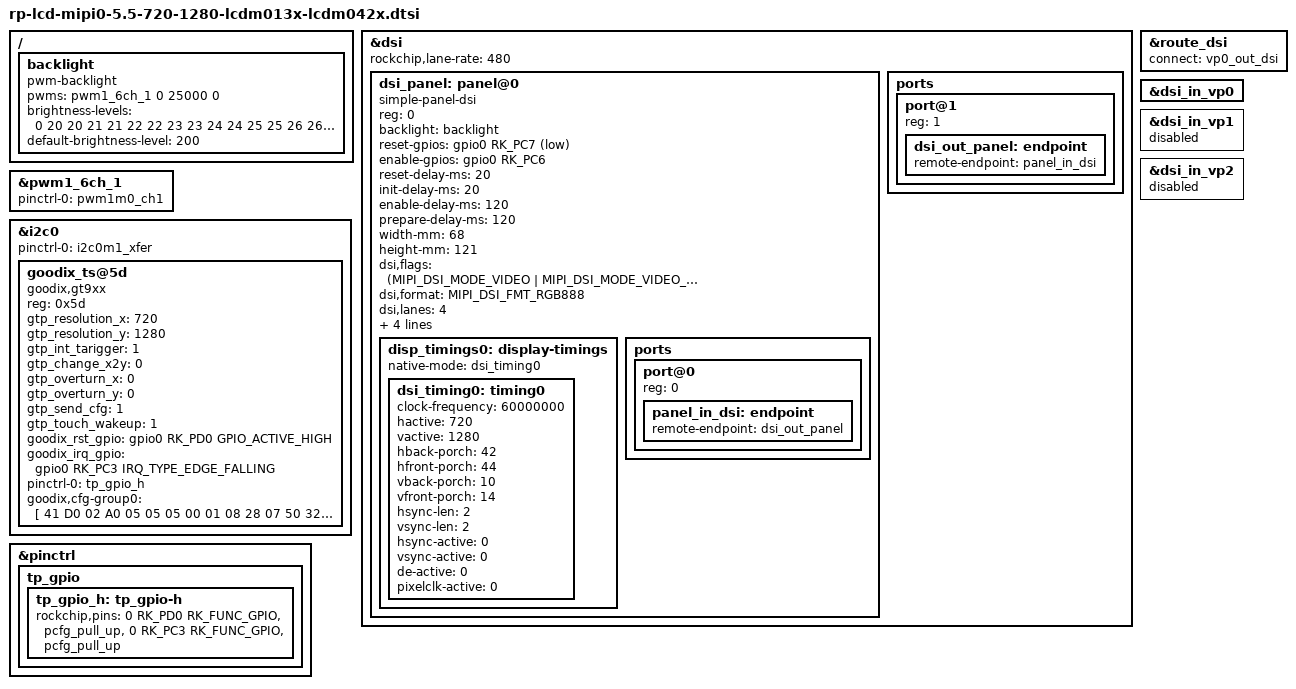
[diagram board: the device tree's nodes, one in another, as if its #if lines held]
/{
    backlight: backlight {
        compatible = "pwm-backlight";
        pwms = <&pwm1_6ch_1 0 25000 0>;
        brightness-levels = <
              0  20  20  21  21  22  22  23
             23  24  24  25  25  26  26  27
             27  28  28  29  29  30  30  31
             31  32  32  33  33  34  34  35
             35  36  36  37  37  38  38  39
             40  41  42  43  44  45  46  47
             48  49  50  51  52  53  54  55
             56  57  58  59  60  61  62  63
             64  65  66  67  68  69  70  71
             72  73  74  75  76  77  78  79
             80  81  82  83  84  85  86  87
             88  89  90  91  92  93  94  95
             96  97  98  99 100 101 102 103
            104 105 106 107 108 109 110 111
            112 113 114 115 116 117 118 119
            120 121 122 123 124 125 126 127
            128 129 130 131 132 133 134 135
            136 137 138 139 140 141 142 143
            144 145 146 147 148 149 150 151
            152 153 154 155 156 157 158 159
            160 161 162 163 164 165 166 167
            168 169 170 171 172 173 174 175
            176 177 178 179 180 181 182 183
            184 185 186 187 188 189 190 191
            192 193 194 195 196 197 198 199
            200 201 202 203 204 205 206 207
            208 209 210 211 212 213 214 215
            216 217 218 219 220 221 222 223
            224 225 226 227 228 229 230 231
            232 233 234 235 236 237 238 239
            240 241 242 243 244 245 246 247
            248 249 250 251 252 253 254 255
        >;
        default-brightness-level = <200>;
    };
};



&dsi {
    status = "okay";
    rockchip,lane-rate = <480>;
    dsi_panel: panel@0 {
        status = "okay";
        compatible = "simple-panel-dsi";
        reg = <0>;
        backlight = <&backlight>;
        
        reset-gpios = <&gpio0 RK_PC7 GPIO_ACTIVE_LOW>;
        enable-gpios = <&gpio0 RK_PC6 GPIO_ACTIVE_HIGH>;
  
	reset-delay-ms = <20>;
        init-delay-ms = <20>;
        enable-delay-ms = <120>;
        prepare-delay-ms = <120>;
 
        width-mm = <68>;
        height-mm = <121>;
        dsi,flags = <(MIPI_DSI_MODE_VIDEO | MIPI_DSI_MODE_VIDEO_BURST |
                  MIPI_DSI_MODE_LPM | MIPI_DSI_MODE_NO_EOT_PACKET)>;
        dsi,format = <MIPI_DSI_FMT_RGB888>;
        dsi,lanes  = <4>;
        panel-init-sequence = [
		39 00 04 B9 F1 12 83
                39 00 1C BA 33 81 05 F9 0E 0E 20 00 00 00 00 00 00 00 44 25 00 91 0A 00 00 02 4F D1 00 00 37
                39 00 05 B8 26 22 20 03
                39 00 04 BF 02 11 00 
                39 00 0B B3 0C 10 0A 50 03 FF 00 00 00 00 
                39 00 0A C0 73 73 50 50 00 00 08 70 00 
                39 00 02 BC 46 
                39 00 02 CC 0B 
                39 00 02 B4 80 
                39 00 04 B2 C8 12 30
                39 00 0F E3 07 07 0B 0B 03 0B 00 00 00 00 FF 00 C0 10
                39 00 0D C1 53 00 1E 1E 77 C1 FF FF AF AF 7F 7F
                39 00 03 B5 07 07
                39 00 03 B6 70 70
                39 00 07 C6 00 00 FF FF 01 FF
                39 00 40 E9 C2 10 05 04 FE 02 81 12 31 45 3F 83 12 91 3B 2A 08 05 00 00 00 00 08 05 00 00 00 00 FF 02 46 02 48 68 88 88 88 80 88 FF 13 57 13 58 78 88 88 88 81 88 00 00 00 00 00 12 B1 3B 00 00 00 00 00 
                39 00 3E EA 00 1A 00 00 00 00 00 00 00 00 00 00 FF 31 75 31 18 78 88 88 88 85 88 FF 20 64 20 08 68 88 88 88 84 88 20 10 00 00 54 00 00 00 00 00 00 00 C0 00 00 0C 00 00 00 00 30 02 A1 00 00 00 00 
                39 00 23 E0 00 05 07 1A 39 3F 33 2C 06 0B 0D 11 13 12 14 10 1A 00 05 07 1A 39 3F 33 2C 06 0B 0D 11 13 12 14 10 1A

            05 78 01 11
            05 00 01 29
        ];

        panel-exit-sequence = [
            05 00 01 28
            05 00 01 10
        ];

        disp_timings0: display-timings {
            native-mode = <&dsi_timing0>;
            dsi_timing0: timing0 {	
                                clock-frequency = <60000000>;
                                hactive = <720>;
                                vactive = <1280>;
                                hback-porch = <42>;
                                hfront-porch = <44>;
                                vback-porch = <10>;
                                vfront-porch = <14>;
                                hsync-len = <2>;
                                vsync-len = <2>;
                                hsync-active = <0>;
                                vsync-active = <0>;
                                de-active = <0>;
                                pixelclk-active = <0>;

            };
        };

        ports {
            #address-cells = <1>;
            #size-cells = <0>;

            port@0 {
                reg = <0>;
                panel_in_dsi: endpoint {
                    remote-endpoint = <&dsi_out_panel>;
                };
            };
        };
    };

    ports {
        #address-cells = <1>;
        #size-cells = <0>;

        port@1 {
            reg = <1>;
            dsi_out_panel: endpoint {
                remote-endpoint = <&panel_in_dsi>;
            };
        };
    };

};

#if defined RP_RK3576S || defined DR4_RK3576X || defined PRO_RK3576X

&route_dsi {
    status = "okay";
    connect = <&vp0_out_dsi>;
};

&pwm1_6ch_1 {
    status = "okay";
    pinctrl-0 = <&pwm1m0_ch1>;
};

&dsi_in_vp0 {
    status = "okay";
};

&dsi_in_vp1 {
    status = "disabled";
};

&dsi_in_vp2 {
    status = "disabled";
};


#else  //rk3576

&route_dsi {
    status = "okay";
};

&pwm1_6ch_1 {
    status = "okay";
    pinctrl-0 = <&pwm1m0_ch1>;
};

//default to hdmi
&dsi_in_vp0 {
    status = "disabled";
};

&dsi_in_vp1 {
    status = "okay";
};

&dsi_in_vp2 {
    status = "disabled";
};

&dsi_in_vopl {
    status = "okay";
};
#endif

//TP
&i2c0 {
    status = "okay";
    pinctrl-names = "default";
    pinctrl-0 = <&i2c0m1_xfer>;

	goodix_ts@5d {
    status = "okay";
		compatible = "goodix,gt9xx";
		reg = <0x5d>;
		gtp_resolution_x = <720>;
		gtp_resolution_y = <1280>;
		gtp_int_tarigger = <1>;
		gtp_change_x2y = <0>;
		gtp_overturn_x = <0>;
		gtp_overturn_y = <0>;
		gtp_send_cfg = <1>;
		gtp_touch_wakeup = <1>;
		
	  goodix_rst_gpio = <&gpio0 RK_PD0 GPIO_ACTIVE_HIGH>;
	  goodix_irq_gpio = <&gpio0 RK_PC3 IRQ_TYPE_EDGE_FALLING>;
   	pinctrl-names = "default";
    pinctrl-0 = <&tp_gpio_h>;
    
     
	goodix,cfg-group0 = [
            41 D0 02 A0 05 05 05 00 01 08 
            28 07 50 32 03 05 00 00 00 00 
            00 00 00 00 00 00 00 89 29 0A 
            5A 5C 31 0D 00 00 00 9A 02 1C 
            00 00 00 00 00 03 64 32 00 00 
            00 50 82 94 C5 02 07 00 00 04 
            DE 20 00 C4 26 00 AD 2E 00 9A 
            38 00 8C 44 00 8C 00 00 00 00 
            00 00 00 00 00 00 00 00 00 00 
            00 00 00 00 00 00 00 00 00 00 
            00 00 00 00 00 00 00 00 00 00 
            00 00 14 12 10 0E 0C 0A 08 06 
            04 02 00 02 04 06 08 0A 0C 0F 
            10 22 21 20 1F 1E 1D 1C 18 16 
            FF FF 96 01];
	};
};

&pinctrl {
    tp_gpio {
		tp_gpio_h: tp_gpio-h {
			rockchip,pins = <0 RK_PD0 RK_FUNC_GPIO &pcfg_pull_up>,
                            <0 RK_PC3 RK_FUNC_GPIO &pcfg_pull_up>;
		};
	};
};


